# ESP32-H21 register map
Vendor: ESPRESSIF SYSTEMS (SHANGHAI) CO., LTD.; Series: ESP32 H-Series; File version: 1
CPU: RV32IMAC r0p0, little endian, no MPU, no FPU, 0 interrupt priority bits
Address unit: 32 bits
Registers are 32-bit, read-write, reset 0x0 unless marked. A register's access mark holds for its fields unless they carry their own. Offsets are from the block's base; [hi:lo] are bit positions; {n}, {i} and the like mark numbered series; 'fields as' and 'values as' point back to an identical list.

## GPIO — General Purpose Input/Output
Base 0x60091000
0x00 STRAP ro — pad strapping register
  [15:0] STRAPPING
0x04 OUT — GPIO output register for GPIO0-29
  [29:0] DATA_ORIG
0x08 OUT_W1TS wo — GPIO output set register for GPIO0-29
  [29:0] OUT_W1TS
0x0C OUT_W1TC wo — GPIO output clear register for GPIO0-29
  [29:0] OUT_W1TC
0x34 ENABLE — GPIO output enable register for GPIO0-29
  [29:0] DATA
0x38 ENABLE_W1TS wo — GPIO output enable set register for GPIO0-29
  [29:0] ENABLE_W1TS
0x3C ENABLE_W1TC wo — GPIO output enable clear register for GPIO0-29
  [29:0] ENABLE_W1TC
0x64 IN ro — GPIO input register for GPIO0-29
  [29:0] DATA_NEXT
0x74 STATUS — GPIO interrupt status register for GPIO0-29
  [29:0] INTERRUPT
0x78 STATUS_W1TS wo — GPIO interrupt status set register for GPIO0-29
  [29:0] STATUS_W1TS
0x7C STATUS_W1TC wo — GPIO interrupt status clear register for GPIO0-29
  [29:0] STATUS_W1TC
0xA4 PROCPU_INT ro — GPIO_PROCPU_INT interrupt status register for GPIO0-29
  [29:0] PROCPU_INT
0xA8 PROCPU_NMI_INT ro — GPIO_PROCPU_NMI_INT interrupt status register for GPIO0-29
  [29:0] PROCPU_NMI_INT
0xC4 STATUS_NEXT ro — GPIO interrupt source register for GPIO0-29
  [29:0] STATUS_INTERRUPT_NEXT
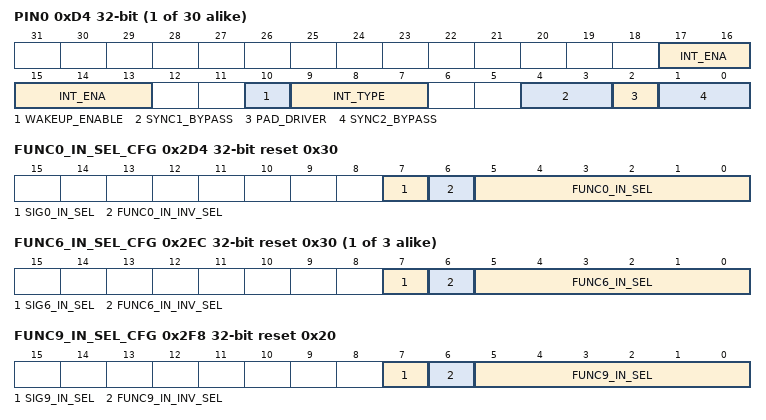
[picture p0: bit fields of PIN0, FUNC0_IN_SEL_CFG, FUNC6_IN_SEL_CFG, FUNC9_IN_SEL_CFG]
{0xD4+4i} PIN{i} (i=0..29) — GPIO pin configuration register
  [17:13] INT_ENA — set bit 13 to enable gpio_procpu_int. set bit 14 to enable gpio_procpu_nmi_int.
  [10] WAKEUP_ENABLE — set this bit to enable GPIO wakeup.(can only wakeup CPU from Light-sleep Mode)
  [9:7] INT_TYPE — set this value to choose interrupt mode. 0:disable GPIO interrupt. 1:trigger at posedge. 2:trigger at negedge. 3:trigger at any edge. 4:valid at low level. 5:valid at high level
  [4:3] SYNC1_BYPASS — set GPIO input_sync1 signal mode. 0:disable. 1:trigger at negedge. 2or3:trigger at posedge.
  [2] PAD_DRIVER — set this bit to select pad driver. 1:open-drain. 0:normal.
  [1:0] SYNC2_BYPASS — set GPIO input_sync2 signal mode. 0:disable. 1:trigger at negedge. 2or3:trigger at posedge.
0x2D4 FUNC0_IN_SEL_CFG reset 0x30 — GPIO input function configuration register
  [7] SIG0_IN_SEL — set this bit to bypass GPIO. 1:do not bypass GPIO. 0:bypass GPIO.
  [6] FUNC0_IN_INV_SEL — set this bit to invert input signal. 1:invert. 0:not invert.
  [5:0] FUNC0_IN_SEL — set this value: s=0-29: connect GPIO[s] to this port. s=0x20: set this port always high level. s=0x30: set this port always low level.
{0x2D4+4i} FUNC{i}_IN_SEL_CFG reset 0x30 (i=6..8) — GPIO input function configuration register
  [7] SIG{i}_IN_SEL — set this bit to bypass GPIO. 1:do not bypass GPIO. 0:bypass GPIO.
  [6] FUNC{i}_IN_INV_SEL — set this bit to invert input signal. 1:invert. 0:not invert.
  [5:0] FUNC{i}_IN_SEL — set this value: s=0-29: connect GPIO[s] to this port. s=0x20: set this port always high level. s=0x30: set this port always low level.
0x2F8 FUNC9_IN_SEL_CFG reset 0x20 — GPIO input function configuration register
  [7] SIG9_IN_SEL — set this bit to bypass GPIO. 1:do not bypass GPIO. 0:bypass GPIO.
  [6] FUNC9_IN_INV_SEL — set this bit to invert input signal. 1:invert. 0:not invert.
  [5:0] FUNC9_IN_SEL — set this value: s=0-29: connect GPIO[s] to this port. s=0x20: set this port always high level. s=0x30: set this port always low level.
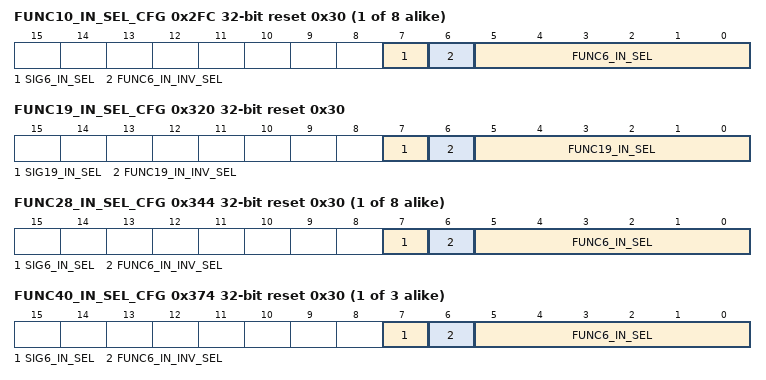
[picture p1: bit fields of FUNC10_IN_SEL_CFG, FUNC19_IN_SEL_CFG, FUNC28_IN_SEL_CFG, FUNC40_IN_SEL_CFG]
{0x2D4+4i} FUNC{i}_IN_SEL_CFG reset 0x30 (i=10..17) — GPIO input function configuration register
  fields as FUNC6_IN_SEL_CFG
0x320 FUNC19_IN_SEL_CFG reset 0x30 — GPIO input function configuration register
  [7] SIG19_IN_SEL — set this bit to bypass GPIO. 1:do not bypass GPIO. 0:bypass GPIO.
  [6] FUNC19_IN_INV_SEL — set this bit to invert input signal. 1:invert. 0:not invert.
  [5:0] FUNC19_IN_SEL — set this value: s=0-29: connect GPIO[s] to this port. s=0x20: set this port always high level. s=0x30: set this port always low level.
{0x2D4+4i} FUNC{i}_IN_SEL_CFG reset 0x30 (i=28..35) — GPIO input function configuration register
  fields as FUNC6_IN_SEL_CFG
{0x2D4+4i} FUNC{i}_IN_SEL_CFG reset 0x30 (i=40..42) — GPIO input function configuration register
  fields as FUNC6_IN_SEL_CFG
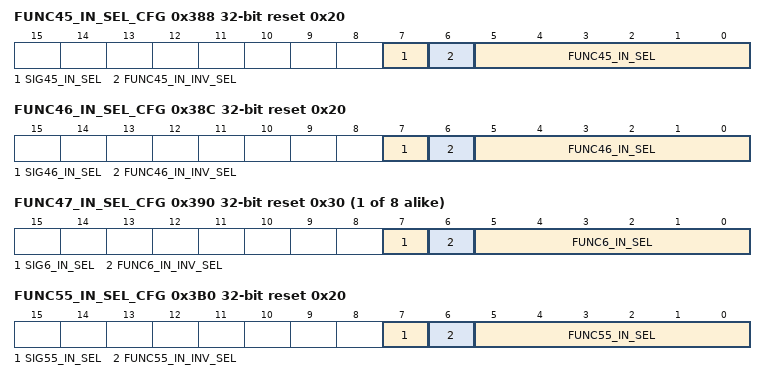
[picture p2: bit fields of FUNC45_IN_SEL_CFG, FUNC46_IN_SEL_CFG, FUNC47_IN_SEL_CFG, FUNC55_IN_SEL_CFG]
0x388 FUNC45_IN_SEL_CFG reset 0x20 — GPIO input function configuration register
  [7] SIG45_IN_SEL — set this bit to bypass GPIO. 1:do not bypass GPIO. 0:bypass GPIO.
  [6] FUNC45_IN_INV_SEL — set this bit to invert input signal. 1:invert. 0:not invert.
  [5:0] FUNC45_IN_SEL — set this value: s=0-29: connect GPIO[s] to this port. s=0x20: set this port always high level. s=0x30: set this port always low level.
0x38C FUNC46_IN_SEL_CFG reset 0x20 — GPIO input function configuration register
  [7] SIG46_IN_SEL — set this bit to bypass GPIO. 1:do not bypass GPIO. 0:bypass GPIO.
  [6] FUNC46_IN_INV_SEL — set this bit to invert input signal. 1:invert. 0:not invert.
  [5:0] FUNC46_IN_SEL — set this value: s=0-29: connect GPIO[s] to this port. s=0x20: set this port always high level. s=0x30: set this port always low level.
{0x2D4+4i} FUNC{i}_IN_SEL_CFG reset 0x30 (i=47..54) — GPIO input function configuration register
  fields as FUNC6_IN_SEL_CFG
0x3B0 FUNC55_IN_SEL_CFG reset 0x20 — GPIO input function configuration register
  [7] SIG55_IN_SEL — set this bit to bypass GPIO. 1:do not bypass GPIO. 0:bypass GPIO.
  [6] FUNC55_IN_INV_SEL — set this bit to invert input signal. 1:invert. 0:not invert.
  [5:0] FUNC55_IN_SEL — set this value: s=0-29: connect GPIO[s] to this port. s=0x20: set this port always high level. s=0x30: set this port always low level.
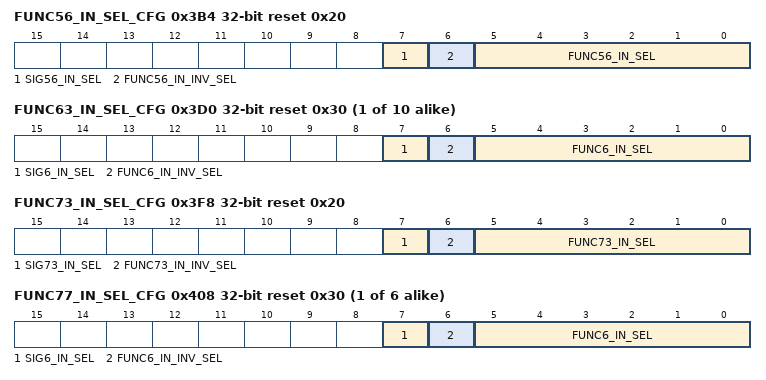
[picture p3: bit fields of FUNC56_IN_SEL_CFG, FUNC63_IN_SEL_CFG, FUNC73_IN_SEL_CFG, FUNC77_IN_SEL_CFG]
0x3B4 FUNC56_IN_SEL_CFG reset 0x20 — GPIO input function configuration register
  [7] SIG56_IN_SEL — set this bit to bypass GPIO. 1:do not bypass GPIO. 0:bypass GPIO.
  [6] FUNC56_IN_INV_SEL — set this bit to invert input signal. 1:invert. 0:not invert.
  [5:0] FUNC56_IN_SEL — set this value: s=0-29: connect GPIO[s] to this port. s=0x20: set this port always high level. s=0x30: set this port always low level.
{0x2D4+4i} FUNC{i}_IN_SEL_CFG reset 0x30 (i=63..72) — GPIO input function configuration register
  fields as FUNC6_IN_SEL_CFG
0x3F8 FUNC73_IN_SEL_CFG reset 0x20 — GPIO input function configuration register
  [7] SIG73_IN_SEL — set this bit to bypass GPIO. 1:do not bypass GPIO. 0:bypass GPIO.
  [6] FUNC73_IN_INV_SEL — set this bit to invert input signal. 1:invert. 0:not invert.
  [5:0] FUNC73_IN_SEL — set this value: s=0-29: connect GPIO[s] to this port. s=0x20: set this port always high level. s=0x30: set this port always low level.
{0x2D4+4i} FUNC{i}_IN_SEL_CFG reset 0x30 (i=77..82) — GPIO input function configuration register
  fields as FUNC6_IN_SEL_CFG
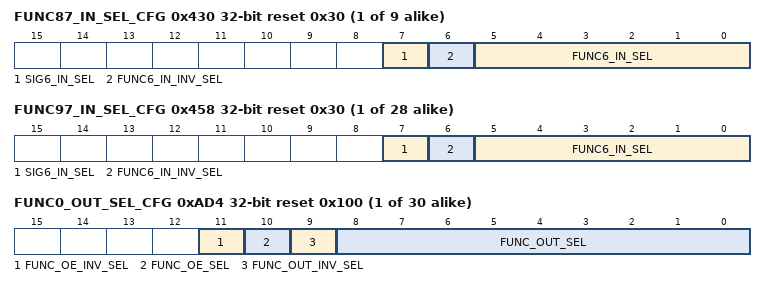
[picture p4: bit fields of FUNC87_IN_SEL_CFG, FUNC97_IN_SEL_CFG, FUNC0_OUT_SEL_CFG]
{0x2D4+4i} FUNC{i}_IN_SEL_CFG reset 0x30 (i=87..95) — GPIO input function configuration register
  fields as FUNC6_IN_SEL_CFG
{0x2D4+4i} FUNC{i}_IN_SEL_CFG reset 0x30 (i=97..124) — GPIO input function configuration register
  fields as FUNC6_IN_SEL_CFG
{0xAD4+4i} FUNC{i}_OUT_SEL_CFG (i=0..29) reset 0x100 — GPIO output function select register
  [11] FUNC_OE_INV_SEL — set this bit to invert output enable signal.1:invert.0:not invert.
  [10] FUNC_OE_SEL — set this bit to select output enable signal.1:use GPIO_ENABLE_REG[n] as output enable signal.0:use peripheral output enable signal.
  [9] FUNC_OUT_INV_SEL — set this bit to invert output signal.1:invert.0:not invert.
  [8:0] FUNC_OUT_SEL — The value of the bits: 0<=s<=256. Set the value to select output signal. s=0-127: output of GPIO[n] equals input of peripheral[s]. s=128: output of GPIO[n] equals GPIO_OUT_REG[n].
0xDF8 CLOCK_GATE reset 0x1 — GPIO clock gate register
  [0] CLK_EN — set this bit to enable GPIO clock gate
0xDFC DATE reset 0x2409110 — GPIO version register
  [27:0] DATE — version register
